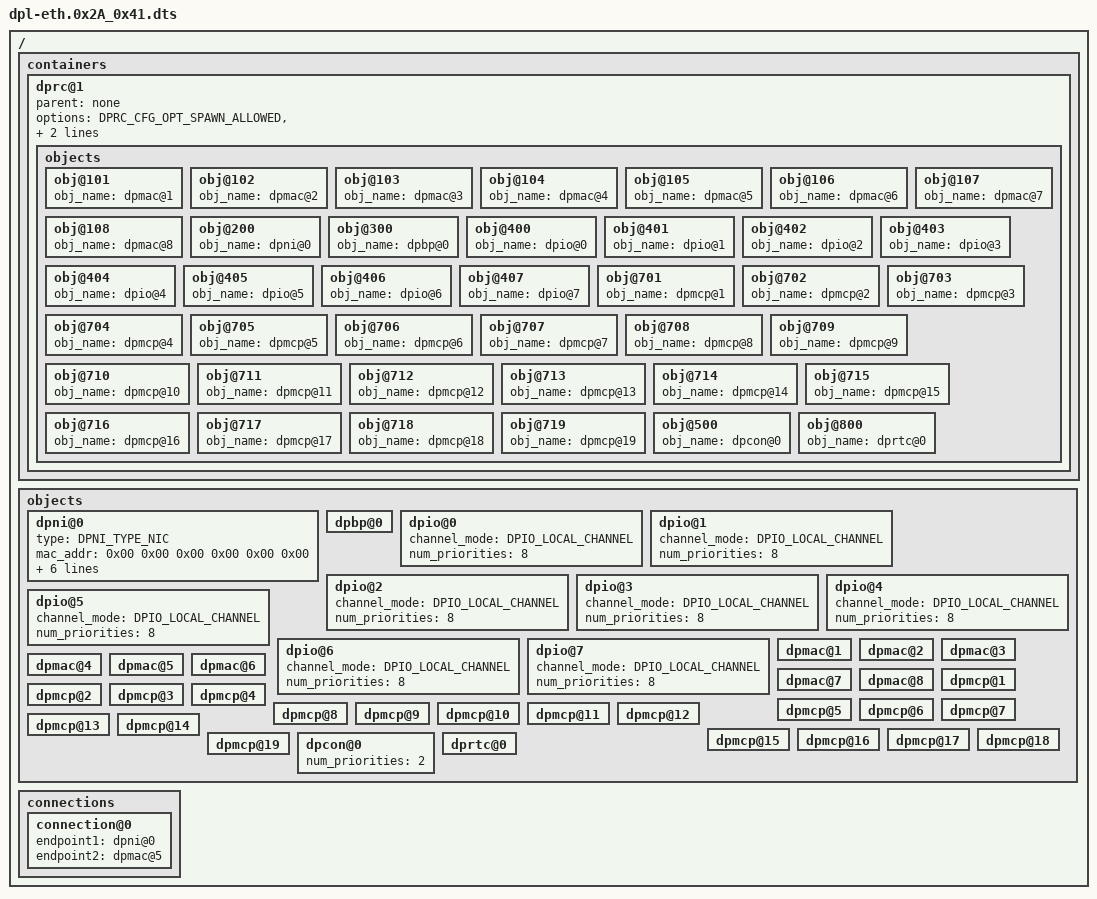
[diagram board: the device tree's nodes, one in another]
/*
 * Copyright 2014-2016 Freescale Semiconductor, Inc.
 * "Bootstrap DPL" for ls2085a RDB boards featuring SerDes 0x2A_0x41.
 * This DPL defines one network interface mapped on the ETH0 copper port.
 * This together with the available DPMCP objects should be enough to boot Linux
 * and to allow the dynamic addition of other objects to the Linux container,
 * using the 'restool' utility.
 */

/dts-v1/;
/ {
	/*****************************************************************
         * Containers
         *****************************************************************/
	containers {
		dprc@1 {
			parent = "none";
			options = "DPRC_CFG_OPT_SPAWN_ALLOWED" , "DPRC_CFG_OPT_ALLOC_ALLOWED", "DPRC_CFG_OPT_IRQ_CFG_ALLOWED";
			objects {
				/* ------------- MACs --------------*/
				obj@101 {
					obj_name = "dpmac@1";
				};
				obj@102 {
					obj_name = "dpmac@2";
				};
				obj@103 {
					obj_name = "dpmac@3";
				};
				obj@104 {
					obj_name = "dpmac@4";
				};
				obj@105 {
					obj_name = "dpmac@5";
				};
				obj@106 {
					obj_name = "dpmac@6";
				};
				obj@107 {
					obj_name = "dpmac@7";
				};
				obj@108 {
					obj_name = "dpmac@8";
				};

				/* ------------ DPNIs --------------*/
				obj@200 {
					obj_name = "dpni@0";
				};

				/* ------------ DPBPs --------------*/
				obj@300 {
					obj_name="dpbp@0";
				};

				/* ------------ DPIOs --------------*/
				obj@400 {
					obj_name = "dpio@0";
				};
				obj@401 {
					obj_name = "dpio@1";
				};
				obj@402 {
					obj_name = "dpio@2";
				};
				obj@403 {
					obj_name = "dpio@3";
				};
				obj@404 {
					obj_name = "dpio@4";
				};
				obj@405 {
					obj_name = "dpio@5";
				};
				obj@406 {
					obj_name = "dpio@6";
				};
				obj@407 {
					obj_name = "dpio@7";
				};

				/* ------------ DPMCPs --------------*/
				obj@701 {
					obj_name="dpmcp@1";
				};
				obj@702 {
					obj_name="dpmcp@2";
				};
				obj@703 {
					obj_name="dpmcp@3";
				};
				obj@704 {
					obj_name="dpmcp@4";
				};
				obj@705 {
					obj_name="dpmcp@5";
				};
				obj@706 {
					obj_name="dpmcp@6";
				};
				obj@707 {
					obj_name="dpmcp@7";
				};
				obj@708 {
					obj_name="dpmcp@8";
				};
				obj@709 {
					obj_name="dpmcp@9";
				};
				obj@710 {
					obj_name="dpmcp@10";
				};
				obj@711 {
					obj_name="dpmcp@11";
				};
				obj@712 {
					obj_name="dpmcp@12";
				};
				obj@713 {
					obj_name="dpmcp@13";
				};
				obj@714 {
					obj_name="dpmcp@14";
				};
				obj@715 {
					obj_name="dpmcp@15";
				};
				obj@716 {
					obj_name="dpmcp@16";
				};
				obj@717 {
					obj_name="dpmcp@17";
				};
				obj@718 {
					obj_name="dpmcp@18";
				};
				obj@719 {
					obj_name="dpmcp@19";
				};

				/* ------------ DPCON --------------*/
				obj@500 {
					obj_name="dpcon@0";
				};

				/* ------------ DPRTC --------------*/
				obj@800 {
					obj_name="dprtc@0";
				};
			};
		};
	};

	/*****************************************************************
         * Objects
         *****************************************************************/
	objects {

		/* ------------ DPNI --------------*/
		dpni@0 {
			type = "DPNI_TYPE_NIC";
			mac_addr = <0x00 0x00 0x00 0x00 0x00 0x00>;
			max_senders = <1>;
			options = "DPNI_OPT_MULTICAST_FILTER", "DPNI_OPT_UNICAST_FILTER";
			max_tcs = <1>;
			max_dist_per_tc = <1>;
			max_dist_key_size = <24>;
		};

		/* ------------ DPBP --------------*/
		dpbp@0 {
		};

		/* ------------ DPIO --------------*/
		dpio@0 {
			channel_mode = "DPIO_LOCAL_CHANNEL";
			num_priorities = <8>;
		};
		dpio@1 {
			channel_mode = "DPIO_LOCAL_CHANNEL";
			num_priorities = <8>;
		};
		dpio@2 {
			channel_mode = "DPIO_LOCAL_CHANNEL";
			num_priorities = <8>;
		};
		dpio@3 {
			channel_mode = "DPIO_LOCAL_CHANNEL";
			num_priorities = <8>;
		};
		dpio@4 {
			channel_mode = "DPIO_LOCAL_CHANNEL";
			num_priorities = <8>;
		};
		dpio@5 {
			channel_mode = "DPIO_LOCAL_CHANNEL";
			num_priorities = <8>;
		};
		dpio@6 {
			channel_mode = "DPIO_LOCAL_CHANNEL";
			num_priorities = <8>;
		};
		dpio@7 {
			channel_mode = "DPIO_LOCAL_CHANNEL";
			num_priorities = <8>;
		};

		/* ------------ DPMAC --------------*/
		/* For SerDes 0x2A_0x41, DPMACs 1-4 are mapped to the optical
		 * PHYs while DPMACs 5-8 are mapped to the Cu PHYs.
		 * Object IDs are relevant, as the MC firmware currently uses
		 * them to identify the DPMACs directly, so dpmac@X is actually
		 * DPMAC#X.
		 */
		dpmac@1 {
		};
		dpmac@2 {
		};
		dpmac@3 {
		};
		dpmac@4 {
		};
		dpmac@5 {
		};
		dpmac@6 {
		};
		dpmac@7 {
		};
		dpmac@8 {
		};

		/* ------------ DPMCP --------------*/
		dpmcp@1 {
		};
		dpmcp@2 {
		};
		dpmcp@3 {
		};
		dpmcp@4 {
		};
		dpmcp@5 {
		};
		dpmcp@6 {
		};
		dpmcp@7 {
		};
		dpmcp@8 {
		};
		dpmcp@9 {
		};
		dpmcp@10 {
		};
		dpmcp@11 {
		};
		dpmcp@12 {
		};
		dpmcp@13 {
		};
		dpmcp@14 {
		};
		dpmcp@15 {
		};
		dpmcp@16 {
		};
		dpmcp@17 {
		};
		dpmcp@18 {
		};
		dpmcp@19 {
		};

		/* ------------ DPCON --------------*/
		dpcon@0 {
			num_priorities=<2>;
		};

		/* ------------ DPRTC --------------*/
		dprtc@0 {
		};
	};

	/*****************************************************************
         * Connections
         *****************************************************************/
	connections {
		connection@0{
			/* First copper port (ETH0 on the RDB chassis) */
			endpoint1 = "dpni@0";
			endpoint2 = "dpmac@5";
		};
	};
};
